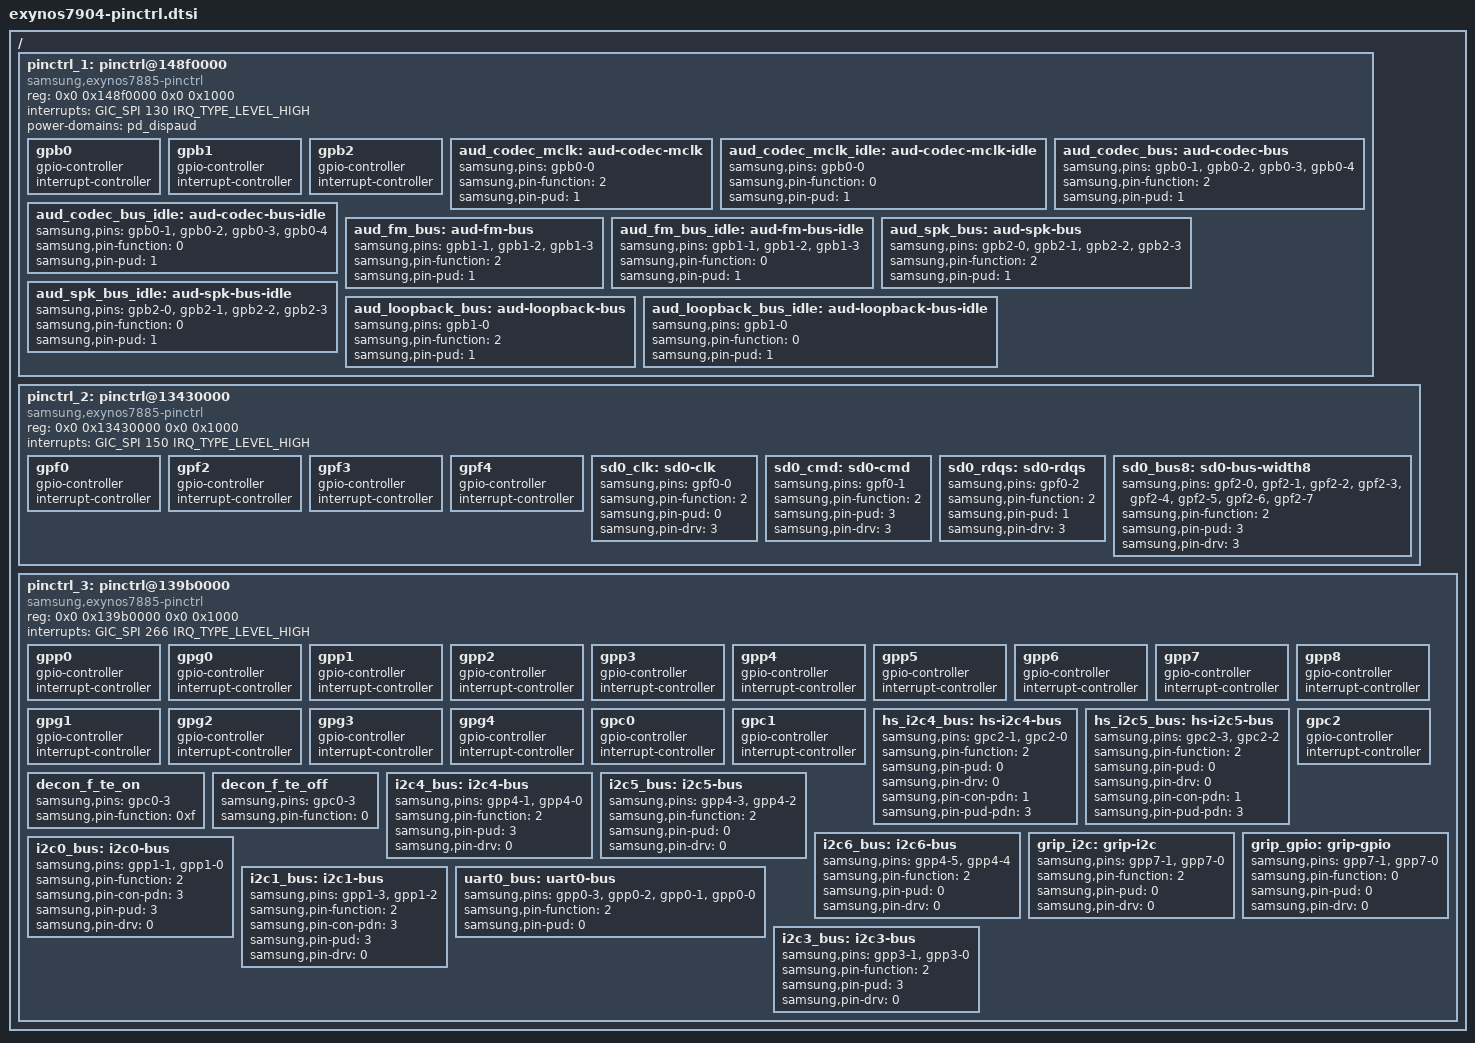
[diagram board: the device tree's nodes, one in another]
// SPDX-License-Identifier: GPL-2.0-only
/*
 * FSYS/TOP nodes and UART0/eMMC groups from the Samsung 4.4
 * exynos7885.dtsi and exynos7885-pinctrl.dtsi. Bank data is Exynos7885,
 * not the incompatible Exynos7 layout. DISPAUD is included for the M20 audio interfaces.
 */

/ {
	pinctrl_1: pinctrl@148f0000 {
		compatible = "samsung,exynos7885-pinctrl";
		reg = <0x0 0x148f0000 0x0 0x1000>;
		interrupts = <GIC_SPI 130 IRQ_TYPE_LEVEL_HIGH>;
		power-domains = <&pd_dispaud>;
		gpb0: gpb0 {
			gpio-controller;
			#gpio-cells = <2>;

			interrupt-controller;
			#interrupt-cells = <2>;
		};

		gpb1: gpb1 {
			gpio-controller;
			#gpio-cells = <2>;

			interrupt-controller;
			#interrupt-cells = <2>;
		};

		gpb2: gpb2 {
			gpio-controller;
			#gpio-cells = <2>;

			interrupt-controller;
			#interrupt-cells = <2>;
		};

		aud_codec_mclk: aud-codec-mclk {
			samsung,pins = "gpb0-0";
			samsung,pin-function = <2>;
			samsung,pin-pud = <1>;
		};

		aud_codec_mclk_idle: aud-codec-mclk-idle {
			samsung,pins = "gpb0-0";
			samsung,pin-function = <0>;
			samsung,pin-pud = <1>;
		};

		aud_codec_bus: aud-codec-bus {
			samsung,pins = "gpb0-1", "gpb0-2", "gpb0-3", "gpb0-4";
			samsung,pin-function = <2>;
			samsung,pin-pud = <1>;
		};

		aud_codec_bus_idle: aud-codec-bus-idle {
			samsung,pins = "gpb0-1", "gpb0-2", "gpb0-3", "gpb0-4";
			samsung,pin-function = <0>;
			samsung,pin-pud = <1>;
		};

		aud_fm_bus: aud-fm-bus {
			samsung,pins = "gpb1-1", "gpb1-2", "gpb1-3";
			samsung,pin-function = <2>;
			samsung,pin-pud = <1>;
		};

		aud_fm_bus_idle: aud-fm-bus-idle {
			samsung,pins = "gpb1-1", "gpb1-2", "gpb1-3";
			samsung,pin-function = <0>;
			samsung,pin-pud = <1>;
		};

		aud_spk_bus: aud-spk-bus {
			samsung,pins = "gpb2-0", "gpb2-1", "gpb2-2", "gpb2-3";
			samsung,pin-function = <2>;
			samsung,pin-pud = <1>;
		};

		aud_spk_bus_idle: aud-spk-bus-idle {
			samsung,pins = "gpb2-0", "gpb2-1", "gpb2-2", "gpb2-3";
			samsung,pin-function = <0>;
			samsung,pin-pud = <1>;
		};

		aud_loopback_bus: aud-loopback-bus{
			samsung,pins = "gpb1-0";
			samsung,pin-function = <2>;
			samsung,pin-pud = <1>;
		};

		aud_loopback_bus_idle: aud-loopback-bus-idle{
			samsung,pins = "gpb1-0";
			samsung,pin-function = <0>;
			samsung,pin-pud = <1>;
		};
	};

	pinctrl_2: pinctrl@13430000 {
		compatible = "samsung,exynos7885-pinctrl";
		reg = <0x0 0x13430000 0x0 0x1000>;
		interrupts = <GIC_SPI 150 IRQ_TYPE_LEVEL_HIGH>;

		gpf0: gpf0 {
			gpio-controller;
			#gpio-cells = <2>;
			interrupt-controller;
			#interrupt-cells = <2>;
			#address-cells = <0>;
		};

		gpf2: gpf2 {
			gpio-controller;
			#gpio-cells = <2>;
			interrupt-controller;
			#interrupt-cells = <2>;
			#address-cells = <0>;
		};

		gpf3: gpf3 {
			gpio-controller;
			#gpio-cells = <2>;
			interrupt-controller;
			#interrupt-cells = <2>;
			#address-cells = <0>;
		};

		gpf4: gpf4 {
			gpio-controller;
			#gpio-cells = <2>;
			interrupt-controller;
			#interrupt-cells = <2>;
			#address-cells = <0>;
		};

		sd0_clk: sd0-clk {
			samsung,pins = "gpf0-0";
			samsung,pin-function = <2>;
			samsung,pin-pud = <0>;
			samsung,pin-drv = <3>;
		};

		sd0_cmd: sd0-cmd {
			samsung,pins = "gpf0-1";
			samsung,pin-function = <2>;
			samsung,pin-pud = <3>;
			samsung,pin-drv = <3>;
		};

		sd0_rdqs: sd0-rdqs {
			samsung,pins = "gpf0-2";
			samsung,pin-function = <2>;
			samsung,pin-pud = <1>;
			samsung,pin-drv = <3>;
		};

		sd0_bus8: sd0-bus-width8 {
			samsung,pins = "gpf2-0", "gpf2-1", "gpf2-2", "gpf2-3",
				       "gpf2-4", "gpf2-5", "gpf2-6", "gpf2-7";
			samsung,pin-function = <2>;
			samsung,pin-pud = <3>;
			samsung,pin-drv = <3>;
		};
	};

	pinctrl_3: pinctrl@139b0000 {
		compatible = "samsung,exynos7885-pinctrl";
		reg = <0x0 0x139b0000 0x0 0x1000>;
		interrupts = <GIC_SPI 266 IRQ_TYPE_LEVEL_HIGH>;

		gpp0: gpp0 {
			gpio-controller;
			#gpio-cells = <2>;
			interrupt-controller;
			#interrupt-cells = <2>;
			#address-cells = <0>;
		};

		gpg0: gpg0 {
			gpio-controller;
			#gpio-cells = <2>;
			interrupt-controller;
			#interrupt-cells = <2>;
			#address-cells = <0>;
		};

		gpp1: gpp1 {
			gpio-controller;
			#gpio-cells = <2>;
			interrupt-controller;
			#interrupt-cells = <2>;
			#address-cells = <0>;
		};

		gpp2: gpp2 {
			gpio-controller;
			#gpio-cells = <2>;
			interrupt-controller;
			#interrupt-cells = <2>;
			#address-cells = <0>;
		};

		gpp3: gpp3 {
			gpio-controller;
			#gpio-cells = <2>;
			interrupt-controller;
			#interrupt-cells = <2>;
			#address-cells = <0>;
		};

		gpp4: gpp4 {
			gpio-controller;
			#gpio-cells = <2>;
			interrupt-controller;
			#interrupt-cells = <2>;
			#address-cells = <0>;
		};

		gpp5: gpp5 {
			gpio-controller;
			#gpio-cells = <2>;
			interrupt-controller;
			#interrupt-cells = <2>;
			#address-cells = <0>;
		};

		gpp6: gpp6 {
			gpio-controller;
			#gpio-cells = <2>;
			interrupt-controller;
			#interrupt-cells = <2>;
			#address-cells = <0>;
		};

		gpp7: gpp7 {
			gpio-controller;
			#gpio-cells = <2>;
			interrupt-controller;
			#interrupt-cells = <2>;
			#address-cells = <0>;
		};

		gpp8: gpp8 {
			gpio-controller;
			#gpio-cells = <2>;
			interrupt-controller;
			#interrupt-cells = <2>;
			#address-cells = <0>;
		};

		gpg1: gpg1 {
			gpio-controller;
			#gpio-cells = <2>;
			interrupt-controller;
			#interrupt-cells = <2>;
			#address-cells = <0>;
		};

		gpg2: gpg2 {
			gpio-controller;
			#gpio-cells = <2>;
			interrupt-controller;
			#interrupt-cells = <2>;
			#address-cells = <0>;
		};

		gpg3: gpg3 {
			gpio-controller;
			#gpio-cells = <2>;
			interrupt-controller;
			#interrupt-cells = <2>;
			#address-cells = <0>;
		};

		gpg4: gpg4 {
			gpio-controller;
			#gpio-cells = <2>;
			interrupt-controller;
			#interrupt-cells = <2>;
			#address-cells = <0>;
		};

		gpc0: gpc0 {
			gpio-controller;
			#gpio-cells = <2>;
			interrupt-controller;
			#interrupt-cells = <2>;
			#address-cells = <0>;
		};

		gpc1: gpc1 {
			gpio-controller;
			#gpio-cells = <2>;
			interrupt-controller;
			#interrupt-cells = <2>;
			#address-cells = <0>;
		};

		/* 4.4 exynos7885-pinctrl.dtsi lines 676-684 (USI0 CH0). */
		hs_i2c4_bus: hs-i2c4-bus {
			samsung,pins = "gpc2-1", "gpc2-0";
			samsung,pin-function = <2>;
			samsung,pin-pud = <0>;
			samsung,pin-drv = <0>;
			samsung,pin-con-pdn = <1>;
			samsung,pin-pud-pdn = <3>;
		};

		hs_i2c5_bus: hs-i2c5-bus {
			samsung,pins = "gpc2-3", "gpc2-2";
			samsung,pin-function = <2>;
			samsung,pin-pud = <0>;
			samsung,pin-drv = <0>;
			samsung,pin-con-pdn = <1>;
			samsung,pin-pud-pdn = <3>;
		};

		gpc2: gpc2 {
			gpio-controller;
			#gpio-cells = <2>;
			interrupt-controller;
			#interrupt-cells = <2>;
			#address-cells = <0>;
		};

		/* TE input of the panel on GPC0-3; stock DTB decon_f_te_on/off. */
		decon_f_te_on: decon_f_te_on {
			samsung,pins = "gpc0-3";
			samsung,pin-function = <0xf>;
		};

		decon_f_te_off: decon_f_te_off {
			samsung,pins = "gpc0-3";
			samsung,pin-function = <0>;
		};

		/* I2C_4: backlight IC (LM3632) bus, 4.4 exynos7885-pinctrl.dtsi:771-776. */
		i2c4_bus: i2c4-bus {
			samsung,pins = "gpp4-1", "gpp4-0";
			samsung,pin-function = <2>;
			samsung,pin-pud = <3>;
			samsung,pin-drv = <0>;
		};

		/* Sensor buses and grip lines, 4.4 exynos7904-m20lte-sensor-r03.dtsi. */
		i2c5_bus: i2c5-bus {
			samsung,pins = "gpp4-3", "gpp4-2";
			samsung,pin-function = <2>;
			samsung,pin-pud = <0>;
			samsung,pin-drv = <0>;
		};

		i2c6_bus: i2c6-bus {
			samsung,pins = "gpp4-5", "gpp4-4";
			samsung,pin-function = <2>;
			samsung,pin-pud = <0>;
			samsung,pin-drv = <0>;
		};

		grip_i2c: grip-i2c {
			samsung,pins = "gpp7-1", "gpp7-0";
			samsung,pin-function = <2>;
			samsung,pin-pud = <0>;
			samsung,pin-drv = <0>;
		};

		grip_gpio: grip-gpio {
			samsung,pins = "gpp7-1", "gpp7-0";
			samsung,pin-function = <0>;
			samsung,pin-pud = <0>;
			samsung,pin-drv = <0>;
		};

		/* 4.4 exynos7885-pinctrl.dtsi:736-752, unchanged pin setup. */
		i2c0_bus: i2c0-bus {
			samsung,pins = "gpp1-1", "gpp1-0";
			samsung,pin-function = <2>;
			samsung,pin-con-pdn = <3>;
			samsung,pin-pud = <3>;
			samsung,pin-drv = <0>;
		};

		/* I2C_CHARGER */
		i2c1_bus: i2c1-bus {
			samsung,pins = "gpp1-3", "gpp1-2";
			samsung,pin-function = <2>;
			samsung,pin-con-pdn = <3>;
			samsung,pin-pud = <3>;
			samsung,pin-drv = <0>;
		};

		/* All four UART0 pins, exactly as in exynos7885-pinctrl.dtsi. */
		uart0_bus: uart0-bus {
			samsung,pins = "gpp0-3", "gpp0-2", "gpp0-1", "gpp0-0";
			samsung,pin-function = <2>;
			samsung,pin-pud = <0>;
		};
	};
};

&pinctrl_3 {
	i2c3_bus: i2c3-bus {
		samsung,pins = "gpp3-1", "gpp3-0";
		samsung,pin-function = <2>;
		samsung,pin-pud = <3>;
		samsung,pin-drv = <0>;
	};
};
